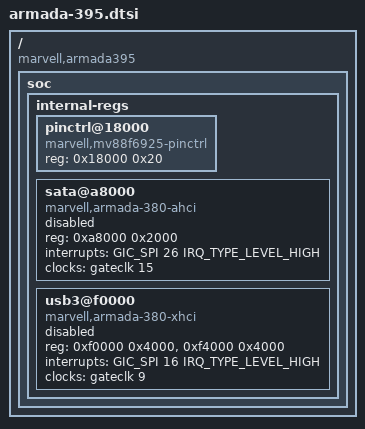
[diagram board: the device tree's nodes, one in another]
/*
 * Device Tree Include file for Marvell Armada 395 SoC.
 *
 * Copyright (C) 2016 Marvell
 *
 * Grzegorz Jaszczyk <jaz@semihalf.com>
 *
 * This file is dual-licensed: you can use it either under the terms
 * of the GPL or the X11 license, at your option. Note that this dual
 * licensing only applies to this file, and not this project as a
 * whole.
 *
 *  a) This file is free software; you can redistribute it and/or
 *     modify it under the terms of the GNU General Public License as
 *     published by the Free Software Foundation; either version 2 of the
 *     License, or (at your option) any later version.
 *
 *     This file is distributed in the hope that it will be useful
 *     but WITHOUT ANY WARRANTY; without even the implied warranty of
 *     MERCHANTABILITY or FITNESS FOR A PARTICULAR PURPOSE.  See the
 *     GNU General Public License for more details.
 *
 * Or, alternatively
 *
 *  b) Permission is hereby granted, free of charge, to any person
 *     obtaining a copy of this software and associated documentation
 *     files (the "Software"), to deal in the Software without
 *     restriction, including without limitation the rights to use
 *     copy, modify, merge, publish, distribute, sublicense, and/or
 *     sell copies of the Software, and to permit persons to whom the
 *     Software is furnished to do so, subject to the following
 *     conditions:
 *
 *     The above copyright notice and this permission notice shall be
 *     included in all copies or substantial portions of the Software.
 *
 *     THE SOFTWARE IS PROVIDED , WITHOUT WARRANTY OF ANY KIND
 *     EXPRESS OR IMPLIED, INCLUDING BUT NOT LIMITED TO THE WARRANTIES
 *     OF MERCHANTABILITY, FITNESS FOR A PARTICULAR PURPOSE AND
 *     NONINFRINGEMENT. IN NO EVENT SHALL THE AUTHORS OR COPYRIGHT
 *     HOLDERS BE LIABLE FOR ANY CLAIM, DAMAGES OR OTHER LIABILITY
 *     WHETHER IN AN ACTION OF CONTRACT, TORT OR OTHERWISE, ARISING
 *     FROM, OUT OF OR IN CONNECTION WITH THE SOFTWARE OR THE USE OR
 *     OTHER DEALINGS IN THE SOFTWARE.
 */

#include "armada-39x.dtsi"

/ {
	compatible = "marvell,armada395", "marvell,armada390";

	soc {
		internal-regs {
			pinctrl@18000 {
				compatible = "marvell,mv88f6925-pinctrl";
				reg = <0x18000 0x20>;
			};

			sata@a8000 {
				compatible = "marvell,armada-380-ahci";
				reg = <0xa8000 0x2000>;
				interrupts = <GIC_SPI 26 IRQ_TYPE_LEVEL_HIGH>;
				clocks = <&gateclk 15>;
				status = "disabled";
			};

			usb3@f0000 {
				compatible = "marvell,armada-380-xhci";
				reg = <0xf0000 0x4000>,<0xf4000 0x4000>;
				interrupts = <GIC_SPI 16 IRQ_TYPE_LEVEL_HIGH>;
				clocks = <&gateclk 9>;
				status = "disabled";
			};
		};
	};
};
